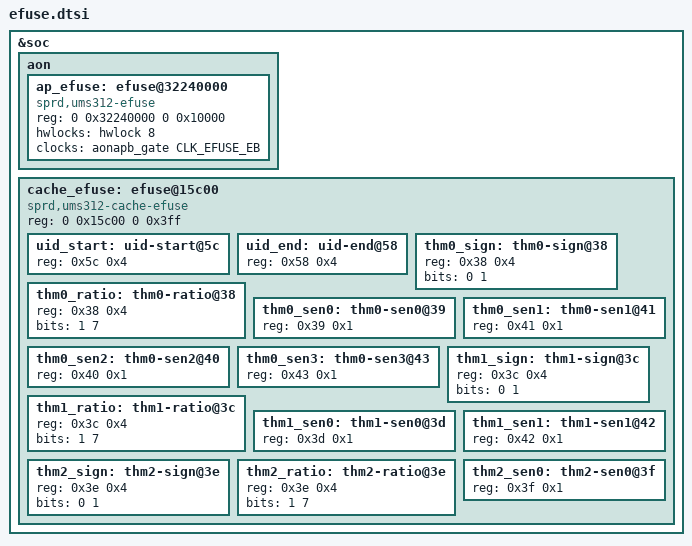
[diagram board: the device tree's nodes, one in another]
// SPDX-License-Identifier: (GPL-2.0+ OR MIT)
/*
 * Unisoc efuse dts file
 *
 * Copyright (C) 2020, Unisoc Inc.
 *
 */

&soc {
	aon: aon {
		ap_efuse: efuse@32240000 {
			status = "okay";
			compatible = "sprd,ums312-efuse";
			reg = <0 0x32240000 0 0x10000>;
			clock-names = "enable";
			hwlocks = <&hwlock 8>;
			clocks = <&aonapb_gate CLK_EFUSE_EB>;
		};
	};

	cache_efuse: efuse@15c00 {
		compatible = "sprd,ums312-cache-efuse";
		reg = <0 0x15c00 0 0x3ff>;
		#address-cells = <1>;
		#size-cells = <1>;

		uid_start: uid-start@5c{
			reg = <0x5c 0x4>;
		};

		uid_end: uid-end@58{
			reg = <0x58 0x4>;
		};

		thm0_sign: thm0-sign@38{
			reg = <0x38 0x4>;
			bits = <0 1>;
		};

		thm0_ratio: thm0-ratio@38{
			reg = <0x38 0x4>;
			bits = <1 7>;
		};

		thm0_sen0: thm0-sen0@39{
			reg = <0x39 0x1>;
		};

		thm0_sen1: thm0-sen1@41{
			reg = <0x41 0x1>;
		};

		thm0_sen2: thm0-sen2@40{
			reg = <0x40 0x1>;
		};

		thm0_sen3: thm0-sen3@43{
			reg = <0x43 0x1>;
		};

		thm1_sign: thm1-sign@3c{
			reg = <0x3c 0x4>;
			bits = <0 1>;
		};

		thm1_ratio: thm1-ratio@3c{
			reg = <0x3c 0x4>;
			bits = <1 7>;
		};

		thm1_sen0: thm1-sen0@3d{
			reg = <0x3d 0x1>;
		};

		thm1_sen1: thm1-sen1@42{
			reg = <0x42 0x1>;
		};

		thm2_sign: thm2-sign@3e{
			reg = <0x3e 0x4>;
			bits = <0 1>;
		};

		thm2_ratio: thm2-ratio@3e{
			reg = <0x3e 0x4>;
			bits = <1 7>;
		};

		thm2_sen0: thm2-sen0@3f{
			reg = <0x3f 0x1>;
		};
	};
};
